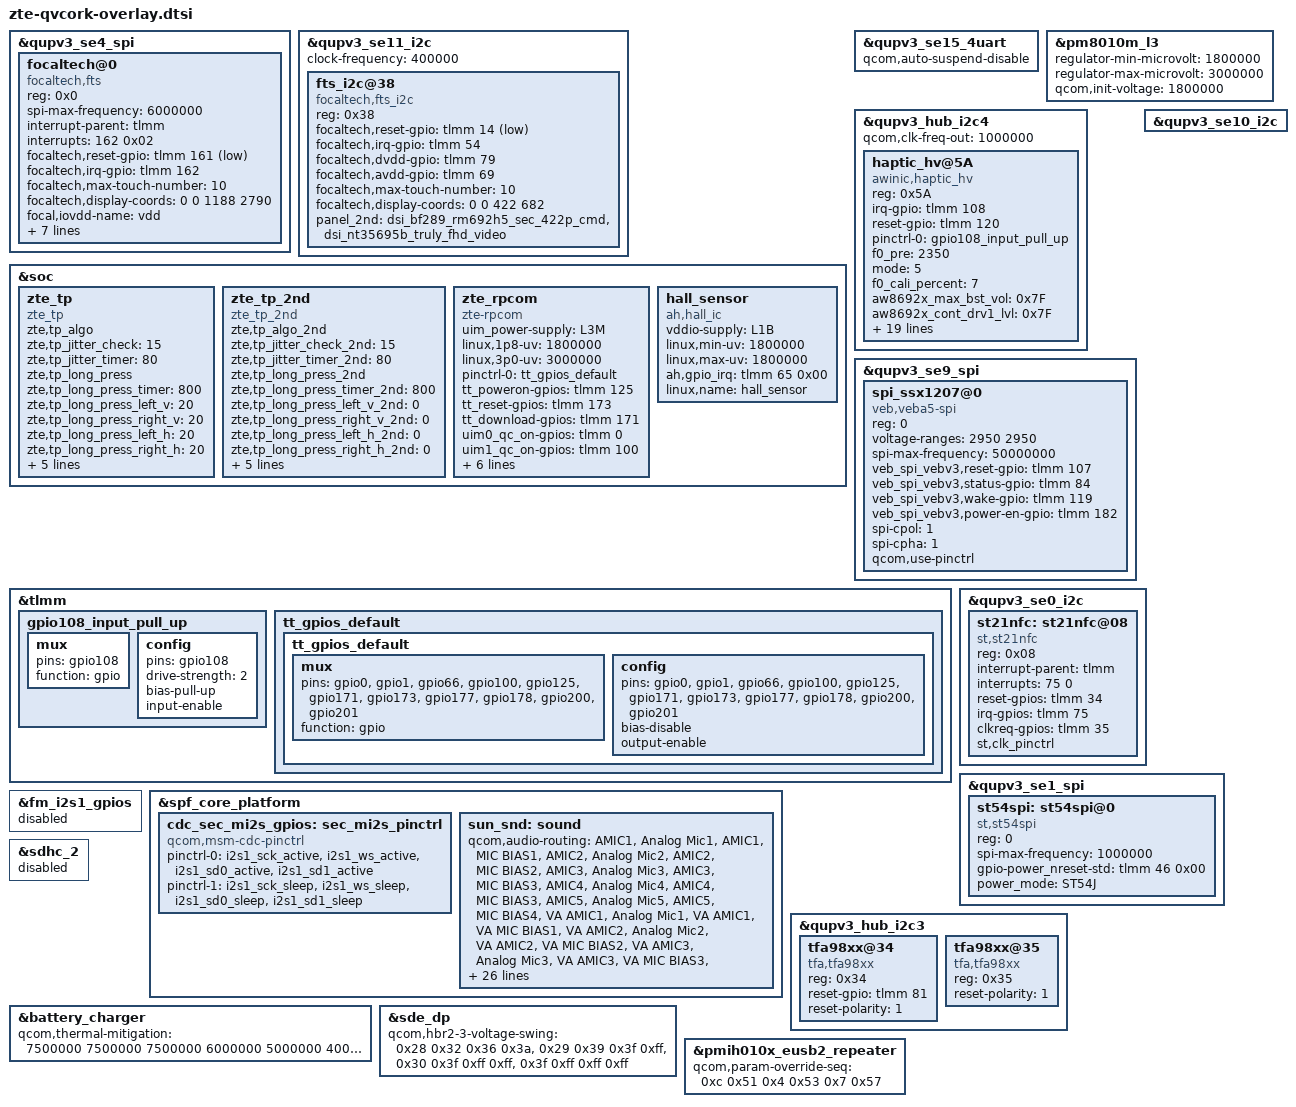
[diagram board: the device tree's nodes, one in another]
/* dtsi for qvcork board (PQ84A31)*/
#include <dt-bindings/gpio/gpio.h>
#include <dt-bindings/input/input.h>
#include <dt-bindings/regulator/qcom,rpmh-regulator-levels.h>
#include "../zte-fingerprint-sun-silead.dtsi"

/* TP FOCAL_TOUCH_FTS3683G Start */
&qupv3_se4_spi {
	status = "ok";

	focaltech@0 {
			compatible = "focaltech,fts";
			reg = <0x0>;
			spi-max-frequency = <6000000>;
			interrupt-parent = <&tlmm>;
			interrupts = <162 0x02>;
			focaltech,reset-gpio = <&tlmm 161 0x01>;
			focaltech,irq-gpio = <&tlmm 162 0x02>;
			focaltech,max-touch-number = <10>;
			focaltech,display-coords =  <0 0 1188 2790>;
			focal,iovdd-name = "vdd";
			vdd-supply = <&L4B>;
			focal,avdd-name = "avdd";
			avdd-supply = <&L14B>;
			/*avdd-enable-gpio = <&tlmm 60 0x0>;*/
			panel = <&dsi_bf288_rm692h5_6p85_dsc_cmd>;

			pinctrl-names = "pmx_ts_active","pmx_ts_suspend","pmx_ts_release";
			pinctrl-0 = <&ts_active>;
			pinctrl-1 = <&ts_int_suspend &ts_reset_suspend>;
			pinctrl-2 = <&ts_release>;
	};
};
/* FOCAL_TOUCH_FTS3683G End */

&qupv3_se11_i2c {
       status = "ok";
       clock-frequency = <400000>;

       fts_i2c@38 {
               compatible = "focaltech,fts_i2c";
               reg = <0x38>;
               focaltech,reset-gpio = <&tlmm 14 0x01>;
               focaltech,irq-gpio =  <&tlmm 54 0x02>;
               /*vdd-supply = <&mt6369_vmc>;*/
               focaltech,dvdd-gpio = <&tlmm 79 0x00>;
               focaltech,avdd-gpio = <&tlmm 69 0x00>;
               focaltech,max-touch-number = <10>;
               focaltech,display-coords =  <0 0 422 682>;
               panel_2nd = <&dsi_bf289_rm692h5_sec_422p_cmd
			    &dsi_nt35695b_truly_fhd_video>;
       };

};

&soc {
	zte_tp:zte_tp {
		compatible = "zte_tp";
		zte,tp_algo;
		zte,tp_jitter_check = <15>;
		zte,tp_jitter_timer = <80>;
		zte,tp_long_press;
		zte,tp_long_press_timer = <800>;
		zte,tp_long_press_left_v = <20>;
		zte,tp_long_press_right_v = <20>;
		zte,tp_long_press_left_h = <20>; /*camera */
		zte,tp_long_press_right_h = <20>; /*charger */
		zte,tp_edge_click_suppression_pixel = <5>;
		zte,ufp_enable;
		zte,ufp_circle_center_x = <540>;
		zte,ufp_circle_center_y = <1703>;
		zte,ufp_circle_radius = <80>;
	};

	zte_tp_2nd:zte_tp_2nd {
		compatible = "zte_tp_2nd";
		zte,tp_algo_2nd;
		zte,tp_jitter_check_2nd = <15>;
		zte,tp_jitter_timer_2nd = <80>;
		zte,tp_long_press_2nd;
		zte,tp_long_press_timer_2nd = <800>;
		zte,tp_long_press_left_v_2nd = <0>;
		zte,tp_long_press_right_v_2nd = <0>;
		zte,tp_long_press_left_h_2nd = <0>; /*camera */
		zte,tp_long_press_right_h_2nd = <0>; /*charger */
		zte,tp_edge_click_suppression_pixel_2nd = <0>;
		zte,ufp_enable_2nd;
		zte,ufp_circle_center_x_2nd = <540>;
		zte,ufp_circle_center_y_2nd = <1703>;
		zte,ufp_circle_radius_2nd = <80>;
	};

	/* add for rpcom drivers*/
	zte_rpcom {
		compatible = "zte-rpcom";
		uim_power-supply = <&L3M>;
		linux,1p8-uv = <1800000>;
		linux,3p0-uv = <3000000>;
		pinctrl-names ="default";
		pinctrl-0 = <&tt_gpios_default>;
		tt_poweron-gpios = <&tlmm 125 GPIO_ACTIVE_HIGH>;
		tt_reset-gpios = <&tlmm 173 GPIO_ACTIVE_HIGH>;
		tt_download-gpios = <&tlmm 171 GPIO_ACTIVE_HIGH>;
		uim0_qc_on-gpios = <&tlmm 0 GPIO_ACTIVE_HIGH>;
		uim1_qc_on-gpios = <&tlmm 100 GPIO_ACTIVE_HIGH>;
		uim0_sw-gpios = <&tlmm 177 GPIO_ACTIVE_HIGH>;
		uim1_sw-gpios = <&tlmm 178 GPIO_ACTIVE_HIGH>;
		tt_rf_sw-gpios = <&tlmm 1 GPIO_ACTIVE_HIGH>;
		uim_hotplug-gpios = <&tlmm 66 GPIO_ACTIVE_HIGH>;
		tt_lna_3v3_en-gpios = <&tlmm 200 GPIO_ACTIVE_HIGH>;
		tt_trx_1p8_en-gpios = <&tlmm 201 GPIO_ACTIVE_HIGH>;
		status = "ok";
	};

	hall_sensor {
		compatible = "ah,hall_ic";
		vddio-supply = <&L1B>;
		linux,min-uv = <1800000>;
		linux,max-uv = <1800000>;
		ah,gpio_irq = <&tlmm 65 0x00>;
		linux,name = "hall_sensor";
	};

};

&qupv3_se15_4uart {
	status = "ok";     /* zte add for rpcom*/
	qcom,auto-suspend-disable;
};

&pm8010m_l3 {
	regulator-min-microvolt = <1800000>;
	regulator-max-microvolt = <3000000>;
	qcom,init-voltage = <1800000>;
};	/* add for rpcom uim power supply */

/* add zte haptic start */
&qupv3_hub_i2c4 {
	status = "ok";
	qcom,clk-freq-out = <1000000>;
	haptic_hv@5A {
		compatible = "awinic,haptic_hv";
		reg = <0x5A>;
		irq-gpio = <&tlmm 108 0>;
		reset-gpio = <&tlmm 120 0>;
		pinctrl-names = "irq_active";
		pinctrl-0 = <&gpio108_input_pull_up>;
		f0_pre = < 2350 >;
		mode = /bits/ 8 < 5 >;
		f0_cali_percent = /bits/ 8 < 7 >;
/******************************aw8692x*******************************/
		aw8692x_max_bst_vol = /bits/ 8 < 0x7F >;
		aw8692x_cont_drv1_lvl = /bits/ 8 < 0x7F >;
		aw8692x_cont_drv2_lvl = /bits/ 8 < 0x26 >; /* 0.9Vrms */
		aw8692x_cont_drv1_time = /bits/ 8 < 0x04 >;
		aw8692x_cont_drv2_time = /bits/ 8 < 0x14 >; /* 10 period */
		aw8692x_cont_drv_width = /bits/ 8 < 0x71 >;
		aw8692x_cont_wait_num = /bits/ 8 < 0x06 >;
		aw8692x_cont_brk_time = /bits/ 8 < 0 >;
		aw8692x_cont_track_margin = /bits/ 8 < 0x0C >;
		aw8692x_brk_bst_md = /bits/ 8 < 0 >;
		aw8692x_cont_tset = /bits/ 8 < 0x06 >;
		aw8692x_cont_bemf_set = /bits/ 8 < 0x02 >;
		aw8692x_cont_bst_brk_gain = /bits/ 8 < 0x05 >;
		aw8692x_cont_brk_gain = /bits/ 8 < 0x08 >;
		aw8692x_duration_time = /bits/ 8 < 20 30 60 >;
		aw8692x_d2s_gain = /bits/ 8 < 0x04 >;
		aw8692x_trig_config = /bits/ 8 < 0 0 0 1 0 2 0 0
						 0 0 0 1 0 2 0 0
						 0 0 0 1 0 2 0 0 >;
		aw8692x_bst_vol_default = /bits/ 8 < 0x48 >; /* 8.0Vrms */
		aw8692x_bst_vol_ram = /bits/ 8 < 0x48 >;
		aw8692x_bst_vol_rtp = /bits/ 8 < 0x48 >;
		/* aw8692x_is_enabled_auto_bst; */
		/* aw8692x_is_enabled_one_wire; */
	};
};

/* add zte safechip begin */
&qupv3_se9_spi {
	status = "ok";

	spi_ssx1207@0 {
	compatible = "veb,veba5-spi";
	reg = <0>;
	voltage-ranges = <2950 2950>;
	spi-max-frequency = <50000000>;
	veb_spi_vebv3,reset-gpio = <&tlmm 107 0x0>;
	veb_spi_vebv3,status-gpio = <&tlmm 84 0x0>;
	veb_spi_vebv3,wake-gpio = <&tlmm 119 0x0>;
	veb_spi_vebv3,power-en-gpio = <&tlmm 182 0>; //3p3
	spi-cpol = <1>;
	spi-cpha = <1>;

	pinctrl-names = "wake_rst_sts_poll_up", "wake_poll_down";

	/*pinctrl-0 = <&gpios0_poll_up>;*/
	/*pinctrl-1 = <&wake0_poll_down>;*/

	qcom,use-pinctrl;
	};
};
/* add zte safechip end */

&tlmm {
	gpio108_input_pull_up: gpio108_input_pull_up {
		mux {
			 pins = "gpio108";
			 function = "gpio";
		};

		config {
			pins = "gpio108";
			drive-strength = <2>;
			bias-pull-up;
			input-enable;
		};
	};

	tt_gpios_default {
		tt_gpios_default: tt_gpios_default {
			mux {
				pins = "gpio0", "gpio1", "gpio66", "gpio100", "gpio125", "gpio171",
					"gpio173", "gpio177", "gpio178", "gpio200", "gpio201";
				function = "gpio";
			};
			config {
				pins = "gpio0", "gpio1", "gpio66", "gpio100", "gpio125", "gpio171",
					"gpio173", "gpio177", "gpio178", "gpio200", "gpio201";
				bias-disable;
				output-enable;
			};
		};
	}; // add for rpcom tiantong pinctrl
};

//add for charger EXTFG2 and sc7603
&qupv3_se10_i2c {
    status = "ok";
};

&qupv3_se0_i2c {
	status = "ok";
	/delete-node/ nq@28;
	st21nfc: st21nfc@08 {
		compatible = "st,st21nfc";
		reg = <0x08>;
		interrupt-parent = <&tlmm>;
		interrupts = <75  0>;
		reset-gpios = <&tlmm 34 0x00>;
		irq-gpios = <&tlmm 75 0x00>;
		//boost-gpios = <&tlmm 90 0x00>;
		//pidle-gpios = <&tlmm 48 0x00>;
		clkreq-gpios = <&tlmm 35 0x00>;
		//clocks = <&clock_rpmh RPMH_RF_CLK3>;
		//clock-names = "nfc_ref_clk";
		st,clk_pinctrl;
		status = "ok";
	};
};

&qupv3_se1_spi {
	status = "ok";
	st54spi: st54spi@0 {
		compatible = "st,st54spi";
		reg = <0>;
		spi-max-frequency = <1000000>;
		/* gpio used as SE_PWR_REQ or SE_nRESET */
		gpio-power_nreset-std = <&tlmm 46 0x00>;

		/* Power management mode: none, ST54H (default), ST54J */
		power_mode = "ST54J";
		status = "ok";
	};
};



&fm_i2s1_gpios {
        status = "disabled";
};

&spf_core_platform  {
	cdc_sec_mi2s_gpios: sec_mi2s_pinctrl {
		status = "ok";
		compatible = "qcom,msm-cdc-pinctrl";
		pinctrl-names = "aud_active", "aud_sleep";
		pinctrl-0 = <&i2s1_sck_active &i2s1_ws_active
        	&i2s1_sd0_active &i2s1_sd1_active>;
		pinctrl-1 = <&i2s1_sck_sleep &i2s1_ws_sleep
        	&i2s1_sd0_sleep &i2s1_sd1_sleep>;
	};
 
	sun_snd: sound {
		qcom,audio-routing =
			"AMIC1", "Analog Mic1",
			"AMIC1", "MIC BIAS1",
			"AMIC2", "Analog Mic2",
			"AMIC2", "MIC BIAS2",
			"AMIC3", "Analog Mic3",
			"AMIC3", "MIC BIAS3",
			"AMIC4", "Analog Mic4",
			"AMIC4", "MIC BIAS3",
			"AMIC5", "Analog Mic5",
			"AMIC5", "MIC BIAS4",
			"VA AMIC1", "Analog Mic1",
			"VA AMIC1", "VA MIC BIAS1",
			"VA AMIC2", "Analog Mic2",
			"VA AMIC2", "VA MIC BIAS2",
			"VA AMIC3", "Analog Mic3",
			"VA AMIC3", "VA MIC BIAS3",
			"VA AMIC4", "Analog Mic4",
			"VA AMIC4", "VA MIC BIAS3",
			"VA AMIC5", "Analog Mic5",
			"VA AMIC5", "VA MIC BIAS4",
			"TX DMIC0", "Digital Mic0",
			"TX DMIC0", "MIC BIAS3",
			"TX DMIC1", "Digital Mic1",
			"TX DMIC1", "MIC BIAS3",
			"TX DMIC2", "Digital Mic2",
			"TX DMIC2", "MIC BIAS1",
			"TX DMIC3", "Digital Mic3",
			"TX DMIC3", "MIC BIAS1",
			"IN1_HPHL", "HPHL_OUT",
			"IN2_HPHR", "HPHR_OUT",
			"IN3_EAR", "AUX_OUT",
			"RX_TX DEC0_INP", "TX DEC0 MUX",
			"RX_TX DEC1_INP", "TX DEC1 MUX",
			"RX_TX DEC2_INP", "TX DEC2 MUX",
			"RX_TX DEC3_INP", "TX DEC3 MUX",
			"TX SWR_INPUT", "WCD_TX_OUTPUT",
			"VA SWR_INPUT", "VA_SWR_CLK",
			"VA SWR_INPUT", "WCD_TX_OUTPUT",
			"VA_AIF1 CAP", "VA_SWR_CLK",
			"VA_AIF2 CAP", "VA_SWR_CLK",
			"VA_AIF3 CAP", "VA_SWR_CLK",
			"VA DMIC0", "Digital Mic0",
			"VA DMIC1", "Digital Mic1",
			"VA DMIC2", "Digital Mic2",
			"VA DMIC3", "Digital Mic3",
			"VA DMIC0", "VA MIC BIAS3",
			"VA DMIC1", "VA MIC BIAS3",
			"VA DMIC2", "VA MIC BIAS1",
			"VA DMIC3", "VA MIC BIAS1";
		qcom,msm-mbhc-usbc-audio-supported = <1>;
		qcom,msm-mbhc-hphl-swh = <0>;
		qcom,msm-mbhc-gnd-swh = <0>;
                
                qcom,mi2s-audio-intf = <1>;
                qcom,sec-mi2s-gpios = <&cdc_sec_mi2s_gpios>;
        };
};

&qupv3_hub_i2c3 {
	status = "okay";
	        tfa98xx@34 {
			        compatible = "tfa,tfa98xx";
					reg = <0x34>;
					reset-gpio = <&tlmm 81 0>;
                                        //irq-gpio = <&tlmm 128 0x00>;
					reset-polarity=<1>;
			};
		tfa98xx@35 {
			        compatible = "tfa,tfa98xx";
					reg = <0x35>;
					//reset-gpio = <&tlmm 81 0>;
                                        //irq-gpio = <&tlmm 127 0x00>;
				        reset-polarity=<1>;
			};
};

&sdhc_2 {
	status = "disabled";
};

&battery_charger {
    /* 
     * external thermal-mitigation for different case, each case 10 levels, base is level=1
     * usb screen off
     * usb screen on
     * wls screen on
     * wls screen off
     */
    qcom,thermal-mitigation = <
        7500000 7500000 7500000 6000000 5000000 4000000 3000000 2000000 1500000 1000000  // USB screen off
        7500000 7500000 6000000 5000000 4000000 3000000 2000000 1500000 1000000 800000   // USB screen on
        7500000 7500000 6000000 4000000 3000000 2000000 1500000 1000000 500000 300000    // WLS screen on
        7500000 6000000 5000000 1000000 1000000 1000000 800000 500000 500000 300000     // WLS screen off
    >;
};

&sde_dp {
	qcom,hbr2-3-voltage-swing = <0x28 0x32 0x36 0x3a>,
				<0x29 0x39 0x3f 0xff>,
				<0x30 0x3f 0xff 0xff>,
				<0x3f 0xff 0xff 0xff>;
};

&pmih010x_eusb2_repeater {
	qcom,param-override-seq =
		/* <value reg_offset> */
		/* Adjust HS trasmit amplitude */
		<0xc 0x51
		/* Disconnect Threshold */
		 0x4 0x53
		/* Tx pre-emphasis tuning */
		 0x7 0x57>;
};
